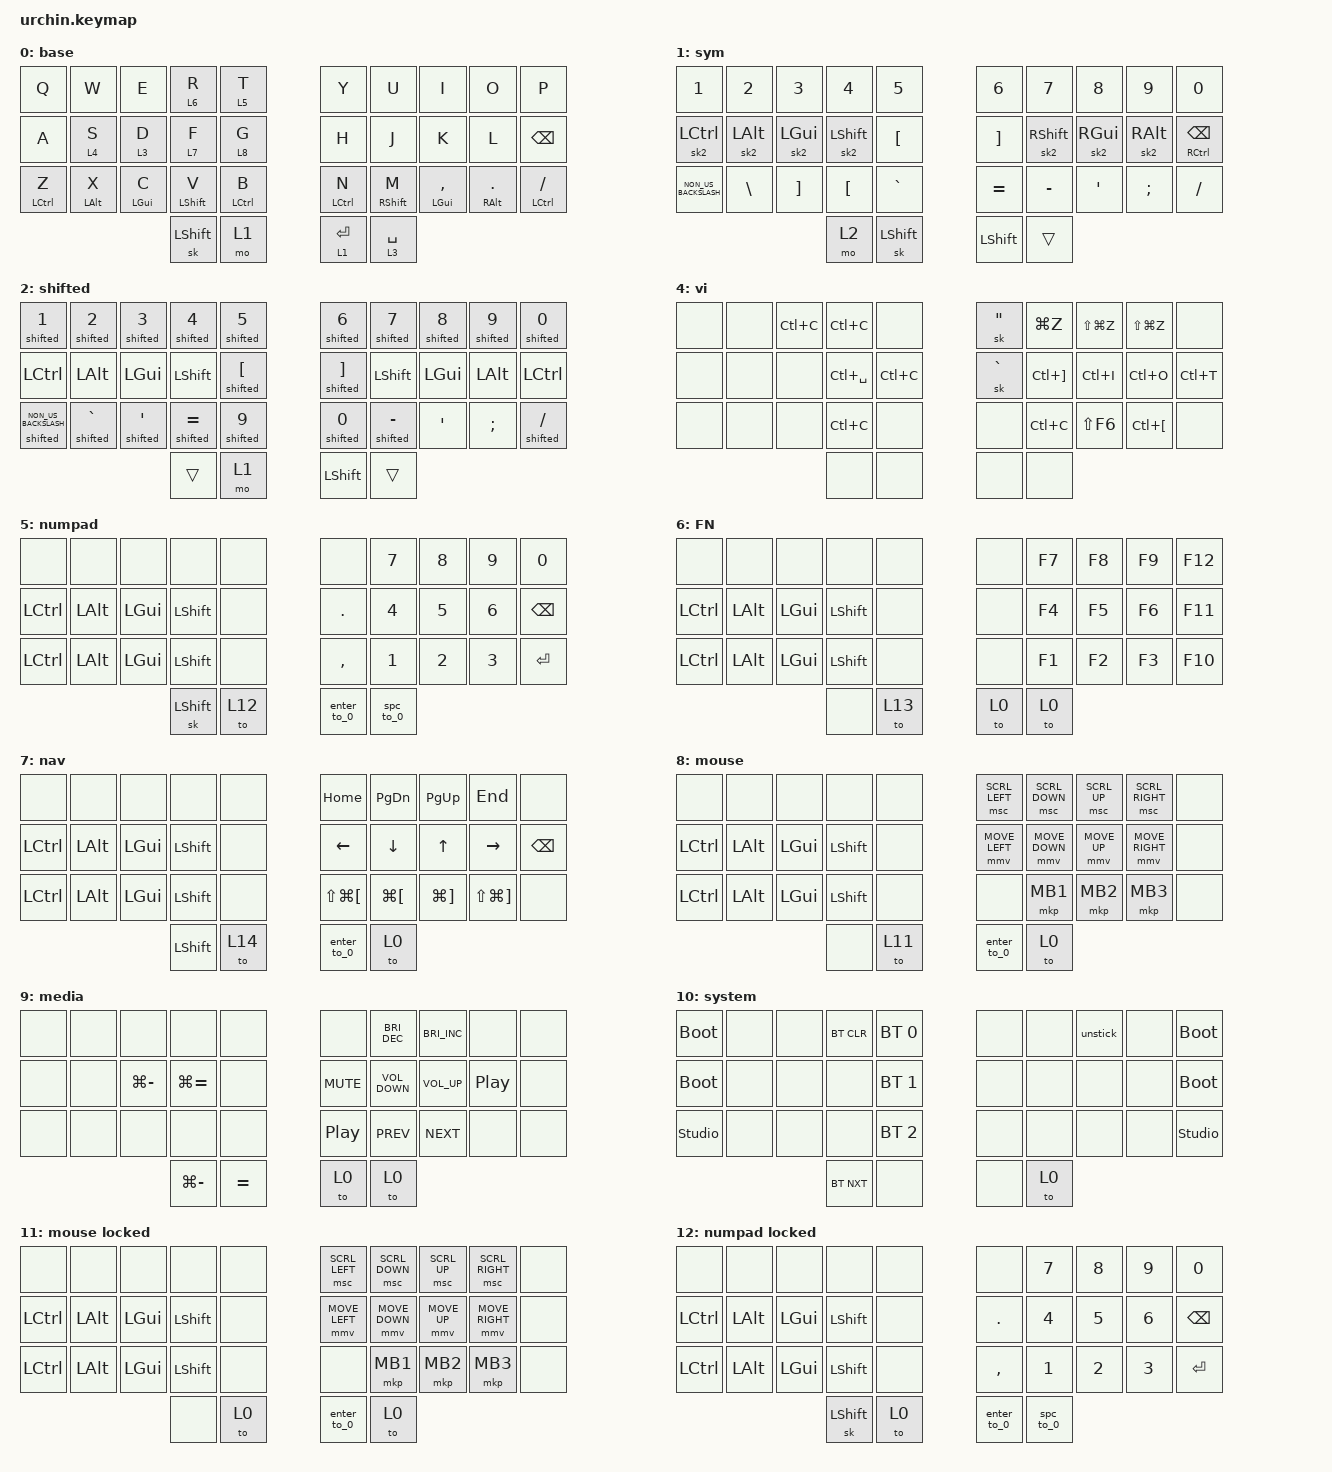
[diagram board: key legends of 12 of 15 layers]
/*
 * Copyright (c) 2020 duckyb
 *
 * SPDX-License-Identifier: MIT
 */

#include <behaviors.dtsi>
#include <dt-bindings/zmk/bt.h>
#include <dt-bindings/zmk/keys.h>
#include <dt-bindings/zmk/pointing.h>
#include "keymap_italian.h"

// Layer definitions

#define BASE 0
#define SYM 1
#define SHIFTED 2
#define MASTER 3
#define VI 4
#define NUMPAD 5
#define FN_LAYER 6
#define NAV 7
#define MOUSE 8
#define MEDIA 9
#define SYSTEM 10
#define MOUSE_LOCKED 11
#define NUMPAD_LOCKED 12
#define FN_LOCKED 13
#define NAV_LOCKED 14

// -----------------

&sk {
    // don't release mods on other mods presses

    quick-release;
    lazy;
    release-after-ms = <1000>;
};

&mt {
    flavor = "balanced";
    tapping-term-ms = <260>;
    hold-while-undecided;
    require-prior-idle-ms = <100>;
};

/ {
    behaviors {
        // Enables holding the first mod-tap key
        // by performing a tap-release-hold sequence.
        // To use it: "&qt KEYCODE1 KEYCODE2"

        qt: quick_tap {
            compatible = "zmk,behavior-hold-tap";
            label = "QUICK_TAP";
            #binding-cells = <2>;
            flavor = "hold-preferred";
            tapping-term-ms = <200>;
            quick-tap-ms = <200>;
            bindings = <&kp>, <&kp>;
        };

        homerow_left: homerow_left {
            compatible = "zmk,behavior-hold-tap";
            label = "HOMEROW_LEFT";
            bindings = <&kp>, <&kp>;

            #binding-cells = <2>;
            tapping-term-ms = <350>;
            require-prior-idle-ms = <100>;
            flavor = "tap-preferred";
            hold-trigger-key-positions = <5 6 7 8 9 15 16 17 18 19 25 26 27 28 29 32 33>;
            hold-trigger-on-release;
        };

        homerow_right: homerow_right {
            compatible = "zmk,behavior-hold-tap";
            label = "HOMEROW_RIGHT";
            bindings = <&kp>, <&kp>;

            #binding-cells = <2>;
            tapping-term-ms = <280>;
            require-prior-idle-ms = <150>;
            flavor = "tap-preferred";
            hold-trigger-on-release;
            hold-trigger-key-positions = <0 1 2 3 4 10 11 12 13 14 20 21 22 23 24 30 31>;
        };

        tap_left: tap_left {
            compatible = "zmk,behavior-hold-tap";
            label = "TAP_LEFT";
            bindings = <&mo>, <&kp>;

            #binding-cells = <2>;
            tapping-term-ms = <260>;
            require-prior-idle-ms = <100>;
            flavor = "balanced";
            hold-trigger-key-positions = <5 6 7 8 9 15 16 17 18 19 25 26 27 28 29 32 33>;
            hold-trigger-on-release;
        };

        tap_right: tap_right {
            compatible = "zmk,behavior-hold-tap";
            label = "TAP_RIGHT";
            bindings = <&mo>, <&kp>;

            #binding-cells = <2>;
            tapping-term-ms = <280>;
            require-prior-idle-ms = <50>;
            flavor = "balanced";
            hold-trigger-key-positions = <0 10 11 12 13 14 20 21 22 23 24 30 31 4 3 2 1>;
            hold-trigger-on-release;
        };

        master_key: master_key {
            compatible = "zmk,behavior-hold-tap";
            label = "MASTER_KEY";
            bindings = <&mo>, <&kp>;

            #binding-cells = <2>;
            tapping-term-ms = <350>;
            require-prior-idle-ms = <100>;
            flavor = "balanced";
            hold-trigger-key-positions = <16 17 7 18 28 27 26 6 8 12 13 22 23 15 5 25 14 24 4 3 2 19 11 10 21 1 20 29 0 9>;
            hold-trigger-on-release;
        };

        macro_layers: macro_layers {
            compatible = "zmk,behavior-hold-tap";
            label = "MACRO_LAYERS";
            bindings = <&tog>, <&sl>;

            #binding-cells = <2>;
            tapping-term-ms = <280>;
            require-prior-idle-ms = <80>;
            flavor = "balanced";
            hold-trigger-on-release;
            hold-trigger-key-positions = <13 12 6 7 8 16 17 18 27 28 26 9 22 23>;
        };

        sk2: sk2 {
            compatible = "zmk,behavior-sticky-key";
            label = "SK2";
            bindings = <&kp>;
            #binding-cells = <1>;
            release-after-ms = <1000>;
            quick-release;
            ignore-modifiers;
        };

        tap_left_strict: tap_left_strict {
            compatible = "zmk,behavior-hold-tap";
            label = "TAP_LEFT_STRICT";
            bindings = <&mo>, <&kp>;

            #binding-cells = <2>;
            tapping-term-ms = <260>;
            require-prior-idle-ms = <120>;
            flavor = "balanced";
            hold-trigger-key-positions = <5 6 7 8 9 15 16 17 18 19 25 26 27 28 29 32 33>;
            hold-trigger-on-release;
        };

        // Four-thumb adaptation of Temper's dedicated System thumb.

        system_shift: system_shift {
            compatible = "zmk,behavior-hold-tap";
            label = "SYSTEM_STICKY_SHIFT";
            #binding-cells = <2>;
            bindings = <&mo>, <&sk>;

            tapping-term-ms = <200>;
            flavor = "tap-preferred";
        };
    };

    macros {
        // sometimes my device thinks a modifier is being held down
        // pressing all modifiers fixes it.

        unstick: unstick {
            label = "ZM_unstick";
            compatible = "zmk,behavior-macro";
            #binding-cells = <0>;
            bindings = <&kp LSHIFT &kp RSHIFT &kp LCTRL &kp RCTRL &kp LALT &kp RALT &kp LGUI &kp RGUI>;
        };

        shifted: shifted {
            compatible = "zmk,behavior-macro-one-param";
            #binding-cells = <1>;
            bindings =
                <&macro_press>,
                <&kp LEFT_SHIFT>,
                <&macro_tap>,
                <&macro_param_1to1 &kp MACRO_PLACEHOLDER>,
                <&macro_release>,
                <&kp LEFT_SHIFT>;

            label = "SHIFTED";
        };

        spc_to_0: spc_to_0 {
            compatible = "zmk,behavior-macro";
            #binding-cells = <0>;
            bindings = <&to 0 &kp SPACE>;
            label = "SPC_TO_0";
        };

        enter_to_0: enter_to_0 {
            compatible = "zmk,behavior-macro";
            #binding-cells = <0>;
            bindings = <&to 0 &kp ENTER>;
            label = "ENTER_TO_0";
        };
    };

    combos {
        compatible = "zmk,combos";

        // both right thumb keys
        // internal-left & external-right thumb keys
        // both left thumb keys
        // left index & middle fingers (home-row)
        // hold control & space for Adobe workflow

        esc {
            bindings = <&kp ESCAPE>;
            key-positions = <16 17>;
            require-prior-idle-ms = <150>;
            layers = <0>;
        };

        ctrlspace {
            bindings = <&kp LC(SPACE)>;
            key-positions = <7 8>;
            require-prior-idle-ms = <350>;
            timeout-ms = <50>;
            layers = <0>;
        };

        system_tog {
            bindings = <&tog 10>;
            key-positions = <1 11 21>;
            require-prior-idle-ms = <250>;
            layers = <0 10>;
        };

        reset_base {
            bindings = <&to 0>;
            key-positions = <0 1 2 3>;
        };

        fn_tap {
            bindings = <&mo 6>;
            key-positions = <2 1>;
            layers = <0 6>;
            require-prior-idle-ms = <280>;
            timeout-ms = <30>;
        };

        fn_tog {
            bindings = <&tog 6>;
            key-positions = <3 2 1>;
            layers = <0 6>;
            timeout-ms = <30>;
            require-prior-idle-ms = <200>;
        };

        mouse_tog {
            bindings = <&tog 8>;
            key-positions = <14 13 12>;
            layers = <0 8>;
            timeout-ms = <80>;
            require-prior-idle-ms = <200>;
        };

        media_tap {
            bindings = <&mo 9>;
            key-positions = <24 23>;
            layers = <0 9>;
            timeout-ms = <30>;
            require-prior-idle-ms = <280>;
        };

        num_tog {
            bindings = <&tog 5>;
            key-positions = <2 3 4>;
            timeout-ms = <30>;
            require-prior-idle-ms = <200>;
            layers = <0 5>;
        };

        tab {
            bindings = <&kp TAB>;
            key-positions = <15 16>;
            timeout-ms = <100>;
            require-prior-idle-ms = <30>;
            layers = <0 1 5 12>;
        };

        sys2 {
            bindings = <&tog 10>;
            key-positions = <8 18 28>;
            layers = <0 10>;
        };

        failsafe {
            bindings = <&studio_unlock>;
            key-positions = <9 19 29>;
            layers = <0>;
            require-prior-idle-ms = <300>;
        };

        mouse {
            bindings = <&mo 8>;
            key-positions = <22 21>;
            timeout-ms = <50>;
            require-prior-idle-ms = <280>;
            layers = <0>;
        };

        media_tog {
            bindings = <&tog 9>;
            key-positions = <23 22 24>;
            layers = <0 9>;
            timeout-ms = <50>;
            require-prior-idle-ms = <280>;
        };

        altgui {
            bindings = <&sk LA(LGUI)>;
            key-positions = <26 27 28>;
            timeout-ms = <100>;
            require-prior-idle-ms = <280>;
            layers = <0>;
        };

        alt_ctrl_gui {
            bindings = <&sk LA(LC(LGUI))>;
            key-positions = <26 27 28>;
            layers = <3>;
        };

        mouse2 {
            bindings = <&mo 8>;
            key-positions = <23 22>;
            layers = <0>;
        };

        enter {
            bindings = <&kp ENTER>;
            key-positions = <7 6>;
            timeout-ms = <50>;
            require-prior-idle-ms = <280>;
            layers = <0>;
        };

        brace {
            bindings = <&kp LEFT_BRACKET>;
            key-positions = <15 6>;
            timeout-ms = <50>;
            require-prior-idle-ms = <280>;
            layers = <0>;
        };

        brace2 {
            bindings = <&kp RIGHT_BRACKET>;
            key-positions = <16 7>;
            timeout-ms = <50>;
            require-prior-idle-ms = <250>;
            layers = <0>;
        };

        bksp {
            bindings = <&kp BACKSPACE>;
            key-positions = <5 6>;
            timeout-ms = <50>;
            require-prior-idle-ms = <250>;
            layers = <0 1>;
        };
    };

    keymap {
        compatible = "zmk,keymap";

        // Base alpha layer

        Base {
            label = "base";
            bindings = <
&kp Q                  &kp W                 &kp E                 &tap_left_strict 6 R        &tap_left_strict 5 T   &kp Y                   &kp U                    &kp I                          &kp O                       &kp P
&kp A                  &tap_left 4 S         &tap_left 3 D         &tap_left 7 F               &tap_left_strict 8 G   &kp H                   &kp J                    &kp K                          &kp L                       &kp BACKSPACE
&homerow_left LCTRL Z  &homerow_left LALT X  &homerow_left LGUI C  &homerow_left LEFT_SHIFT V  &homerow_left LCTRL B  &homerow_right LCTRL N  &homerow_right RSHIFT M  &homerow_right LEFT_GUI COMMA  &homerow_right RALT PERIOD  &homerow_right LCTRL SLASH
                                                                   &sk LEFT_SHIFT              &mo 1                  &master_key 1 ENTER     &master_key 3 SPACE
            >;
        };

        sym_layer {
            label = "sym";
            bindings = <
&kp N1                &kp N2         &kp N3             &kp N4            &kp N5          &kp N6          &kp N7      &kp N8     &kp N9         &kp N0
&sk2 LCTRL            &sk2 LALT      &sk2 LGUI          &sk2 LSHFT        &kp LBKT        &kp RBKT        &sk2 RSHFT  &sk2 RGUI  &sk2 RALT      &homerow_right RCTRL BACKSPACE
&kp NON_US_BACKSLASH  &kp BACKSLASH  &kp RIGHT_BRACKET  &kp LEFT_BRACKET  &kp GRAVE       &kp EQUAL       &kp MINUS   &kp SQT    &kp SEMICOLON  &kp FSLH
                                                        &mo 2             &sk LEFT_SHIFT  &kp LEFT_SHIFT  &trans
            >;
        };

        Shifted {
            label = "shifted";
            bindings = <
&shifted N1                &shifted N2     &shifted N3    &shifted N4     &shifted N5    &shifted N6     &shifted N7     &shifted N8  &shifted N9  &shifted N0
&kp LCTRL                  &kp LALT        &kp LGUI       &kp LSHFT       &shifted LBKT  &shifted RBKT   &kp LSHFT       &kp LGUI     &kp LALT     &kp LCTRL
&shifted NON_US_BACKSLASH  &shifted GRAVE  &shifted APOS  &shifted EQUAL  &shifted N9    &shifted N0     &shifted MINUS  &kp SQT      &kp SEMI     &shifted SLASH
                                                          &trans          &mo 1          &kp LEFT_SHIFT  &trans
            >;
        };

        Master {
            bindings = <
&none  &none          &none                 &kp LG(MINUS)         &kp LG(EQUAL)             &kp LG(A)      &kp LG(C)          &kp LG(V)      &kp LG(X)      &kp LG(A)
&none  &kp LG(SPACE)  &kp LA(LC(LEFT_GUI))  &sk LA(LC(LEFT_GUI))  &sk LS(LA(LC(LEFT_GUI)))  &kp LG(TILDE)  &kp ENTER          &kp BACKSPACE  &kp TAB        &kp LC(LEFT_BRACKET)
&none  &none          &kp LG(SPACE)         &kp LS(LG(SPACE))     &kp LG(LS(J))             &none          &kp LA(BACKSPACE)  &kp DELETE     &kp LG(ENTER)  &none
                                            &kp LEFT_SHIFT        &kp LEFT_GUI              &kp LALT       &kp LCTRL
            >;

            label = "master";
        };

        Vi {
            bindings = <
&none  &none  &kp LC(C)  &kp LC(C)      &none      &sk DOUBLE_QUOTES  &kp LG(Z)              &kp LS(LG(Z))  &kp LS(LG(Z))         &none
&none  &none  &none      &kp LC(SPACE)  &kp LC(C)  &sk GRAVE          &kp LC(RIGHT_BRACKET)  &kp LC(I)      &kp LC(O)             &kp LC(T)
&none  &none  &none      &kp LC(C)      &none      &none              &kp LC(C)              &kp LS(F6)     &kp LC(LEFT_BRACKET)  &none
                         &none          &none      &none              &none
            >;

            label = "vi";
        };

        Numpad {
            bindings = <
&none      &none     &none     &none           &none   &none        &kp N7     &kp N8  &kp N9  &kp N0
&kp LCTRL  &kp LALT  &kp LGUI  &kp LSHFT       &none   &kp DOT      &kp N4     &kp N5  &kp N6  &kp BSPC
&kp LCTRL  &kp LALT  &kp LGUI  &kp LSHFT       &none   &kp COMMA    &kp N1     &kp N2  &kp N3  &kp ENTER
                               &sk LEFT_SHIFT  &to 12  &enter_to_0  &spc_to_0
            >;

            label = "numpad";
        };

        FN {
            label = "FN";
            bindings = <
&none      &none     &none     &none      &none   &none  &kp F7  &kp F8  &kp F9  &kp F12
&kp LCTRL  &kp LALT  &kp LGUI  &kp LSHFT  &none   &none  &kp F4  &kp F5  &kp F6  &kp F11
&kp LCTRL  &kp LALT  &kp LGUI  &kp LSHFT  &none   &none  &kp F1  &kp F2  &kp F3  &kp F10
                               &none      &to 13  &to 0  &to 0
            >;
        };

        Nav {
            bindings = <
&none      &none     &none     &none           &none   &kp HOME                  &kp PAGE_DOWN         &kp PAGE_UP            &kp END                    &none
&kp LCTRL  &kp LALT  &kp LGUI  &kp LSHFT       &none   &kp LEFT                  &kp DOWN              &kp UP                 &kp RIGHT                  &kp BACKSPACE
&kp LCTRL  &kp LALT  &kp LGUI  &kp LSHFT       &none   &kp LS(LG(LEFT_BRACKET))  &kp LG(LEFT_BRACKET)  &kp LG(RIGHT_BRACKET)  &kp LS(LG(RIGHT_BRACKET))  &none
                               &kp LEFT_SHIFT  &to 14  &enter_to_0               &to 0
            >;

            label = "nav";
        };

        Mouse {
            bindings = <
&none      &none     &none     &none      &none   &msc SCRL_LEFT  &msc SCRL_DOWN  &msc SCRL_UP  &msc SCRL_RIGHT  &none
&kp LCTRL  &kp LALT  &kp LGUI  &kp LSHFT  &none   &mmv MOVE_LEFT  &mmv MOVE_DOWN  &mmv MOVE_UP  &mmv MOVE_RIGHT  &none
&kp LCTRL  &kp LALT  &kp LGUI  &kp LSHFT  &none   &none           &mkp MB1        &mkp MB2      &mkp MB3         &none
                               &none      &to 11  &enter_to_0     &to 0
            >;

            label = "mouse";
        };

        Media {
            bindings = <
&none  &none  &none          &none          &none      &none             &kp C_BRIGHTNESS_DEC  &kp C_BRIGHTNESS_INC  &none             &none
&none  &none  &kp LG(MINUS)  &kp LG(EQUAL)  &none      &kp C_MUTE        &kp C_VOLUME_DOWN     &kp C_VOLUME_UP       &kp C_PLAY_PAUSE  &none
&none  &none  &none          &none          &none      &kp C_PLAY_PAUSE  &kp C_PREV            &kp C_NEXT            &none             &none
                             &kp LG(MINUS)  &kp EQUAL  &to 0             &to 0
            >;

            label = "media";
        };

        System {
            label = "system";
            bindings = <
&bootloader     &none  &none  &bt BT_CLR  &bt BT_SEL 0  &none  &none  &unstick  &none  &bootloader
&bootloader     &none  &none  &none       &bt BT_SEL 1  &none  &none  &none     &none  &bootloader
&studio_unlock  &none  &none  &none       &bt BT_SEL 2  &none  &none  &none     &none  &studio_unlock
                              &bt BT_NXT  &none         &none  &to 0
            >;
        };

        MouseLocked {
            label = "mouse locked";
            bindings = <
&none      &none     &none     &none      &none  &msc SCRL_LEFT  &msc SCRL_DOWN  &msc SCRL_UP  &msc SCRL_RIGHT  &none
&kp LCTRL  &kp LALT  &kp LGUI  &kp LSHFT  &none  &mmv MOVE_LEFT  &mmv MOVE_DOWN  &mmv MOVE_UP  &mmv MOVE_RIGHT  &none
&kp LCTRL  &kp LALT  &kp LGUI  &kp LSHFT  &none  &none           &mkp MB1        &mkp MB2      &mkp MB3         &none
                               &none      &to 0  &enter_to_0     &to 0
            >;
        };

        NumpadLocked {
            label = "numpad locked";
            bindings = <
&none      &none     &none     &none           &none  &none        &kp N7     &kp N8  &kp N9  &kp N0
&kp LCTRL  &kp LALT  &kp LGUI  &kp LSHFT       &none  &kp DOT      &kp N4     &kp N5  &kp N6  &kp BSPC
&kp LCTRL  &kp LALT  &kp LGUI  &kp LSHFT       &none  &kp COMMA    &kp N1     &kp N2  &kp N3  &kp ENTER
                               &sk LEFT_SHIFT  &to 0  &enter_to_0  &spc_to_0
            >;
        };

        FNLocked {
            label = "FN locked";
            bindings = <
&none      &none     &none     &none      &none  &none  &kp F7  &kp F8  &kp F9  &kp F12
&kp LCTRL  &kp LALT  &kp LGUI  &kp LSHFT  &none  &none  &kp F4  &kp F5  &kp F6  &kp F11
&kp LCTRL  &kp LALT  &kp LGUI  &kp LSHFT  &none  &none  &kp F1  &kp F2  &kp F3  &kp F10
                               &none      &to 0  &to 0  &to 0
            >;
        };

        NAVLocked {
            label = "nav_locked";
            bindings = <
&none      &none     &none     &none           &none           &kp HOME                  &kp PAGE_DOWN         &kp PAGE_UP            &kp END                    &none
&kp LCTRL  &kp LALT  &kp LGUI  &kp LSHFT       &none           &kp LEFT                  &kp DOWN              &kp UP                 &kp RIGHT                  &kp BACKSPACE
&kp LCTRL  &kp LALT  &kp LGUI  &kp LSHFT       &none           &kp LS(LG(LEFT_BRACKET))  &kp LG(LEFT_BRACKET)  &kp LG(RIGHT_BRACKET)  &kp LS(LG(RIGHT_BRACKET))  &none
                               &kp LEFT_SHIFT  &kp LEFT_SHIFT  &enter_to_0               &to 0
            >;
        };
    };
};
